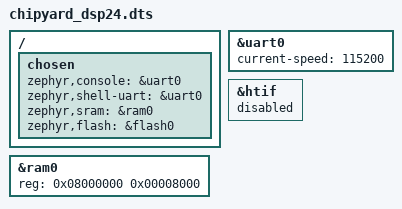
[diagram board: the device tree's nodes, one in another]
/dts-v1/;

#include <chipyard/chipyard-riscv64.dtsi>

/ {
	chosen {
		zephyr,console= &uart0;
		zephyr,shell-uart = &uart0;
		zephyr,sram = &ram0;
		zephyr,flash = &flash0;
	};
};

&uart0 {
	status = "okay";
	current-speed = <115200>;  // Set appropriate baud rate
};

&htif {
	status = "disabled";
};

&ram0 {
	reg = < 0x08000000 0x00008000 >;
};



